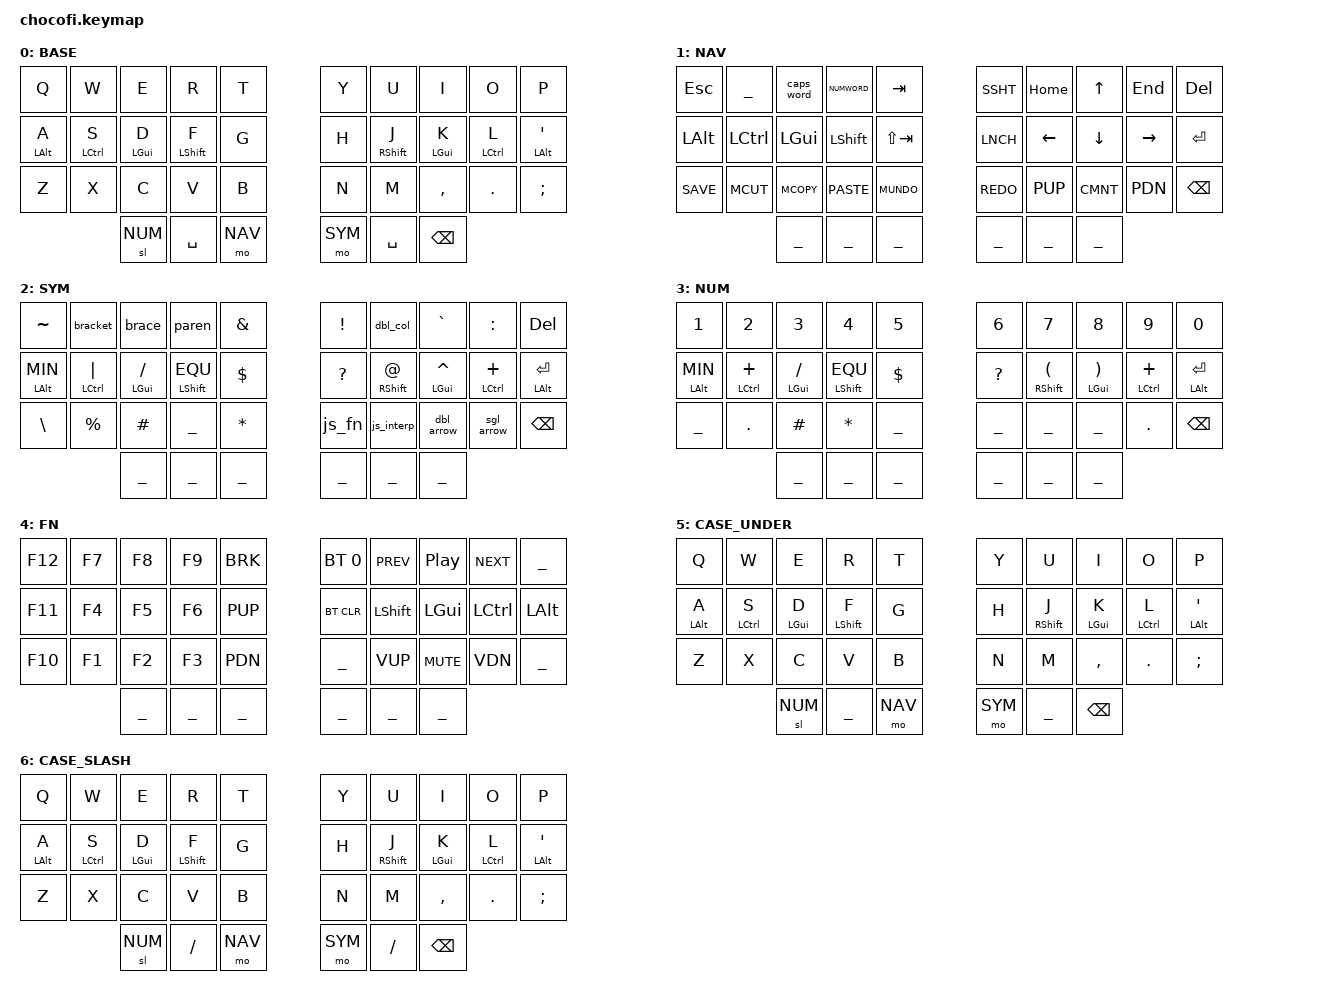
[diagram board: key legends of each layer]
/*
 * Copyright (c) 2020 The ZMK Contributors
 *
 * SPDX-License-Identifier: MIT
 */

#include <behaviors.dtsi>
#include <dt-bindings/zmk/keys.h>
#include <dt-bindings/zmk/bt.h>
#include <behaviors/num_word.dtsi>
#include "zmk-helpers/helper.h"
#include "zmk-helpers/key-labels/36.h"

#define BASE        0
#define NAV         1
#define SYM         2
#define NUM         3
#define FN          4
#define CASE_UNDER  5
#define CASE_SLASH  6

#define QUICK_TAP_MS 75

#include "keycodes.dtsi"
#include "autolayer.dtsi"
#include "layers.dtsi"
#include "combos.dtsi"

/ {
        keymap {
                compatible = "zmk,keymap";

                BASE {
// ------------------------------------------------------------------
// |  Q  |  W  |  E  |  R  |  T  |   |  Y  |  U  |  I   |  O  |  P  |
// |  A  |  S  |  D  |  F  |  G  |   |  H  |  J  |  K   |  L  |  '  |
// |  Z  |  X  |  C  |  V  |  B  |   |  N  |  M  |  ,   |  .  |  ;  |
//             | NUM | SPC | NAV |   | SYM | SPC | BSPC |
                        bindings = <
   &kp Q       &kp W        &kp E       &kp R        &kp T     &kp Y &kp U        &kp I       &kp O        &kp P   
   &hml LALT A &hml LCTRL S &hml LGUI D &hml LSHFT F &kp G     &kp H &hmr RSHFT J &hmr LGUI K &hmr LCTRL L &hmr LALT SQT
   &kp Z       &kp X        &kp C       &kp V        &kp B     &kp N &kp M        &kp COMMA   &kp DOT      &kp SEMI
                                  &sl NUM &kp SPACE &mo NAV    &mo SYM &kp SPACE &kp BSPC
                        >;
                };
                    
                NAV {
// --------------------------------------------------------------------------------------------------
// | ESC  | CASE_PATH  |  CASE_CAPS  | numword |  Tab   |   | ssht   | home |  up   |  end  |  del  |
// | LA   | LC         | LG          | LS      | LS(Tb) |   | launch | left |  down | right | enter |
// | save | cut        | copy        | paste   | undo   |   | redo   | pgup |  cmnt | pgdn  |  bspc |
//                                 | NUM | SPC | NAV    |   | SYM | SPC | BSPC |
                        bindings = <
   &kp ESC   ___       &caps_word NUMWORD   &kp TAB        SSHT &kp HOME &kp UP   &kp END   &kp DEL 
   &kp LALT  &kp LCTRL &kp LGUI  &kp LSHFT &kp LS(TAB)    LNCH &kp LEFT &kp DOWN &kp RIGHT &kp RET
   SAVE      MCUT      MCOPY     PASTE     MUNDO          REDO &kp PUP  CMNT     &kp PDN   &kp BSPC
                          	           ___ ___ ___   ___ ___ ___
                        >;
                };

                SYM {
// -----------------------------------------------------------------
// |  ~  | [] | {} | () |  &  |   |  !  |  ::   |  `  |  :  | del  |
// |  -  |  | |  / |  = |  $  |   |  ?  |  @    |  ^  |  +  | ret  |
// |  \  |  % |  # |  _ |  *  |   |  fn | `${}` |  => |  -> | back |
//             | NUM | SPC | NAV |   | SYM | SPC | BSPC |
                        bindings = <
   &kp TILDE     &bracket        &brace         &paren         &kp AMPS     &kp EXCL  &dbl_col      &kp GRAVE       &kp COLON       &kp DEL
   &hml LALT MIN &hml LCTRL PIPE &hml LGUI FSLH &hml LSHFT EQU &kp DLLR     &kp QMARK &hmr RSHFT AT &hmr LGUI CARET &hmr LCTRL PLUS &hmr LALT RET
   &kp BSLH      &kp PRCNT       &kp HASH       &kp UNDER      &kp ASTRK    &js_fn    &js_interp    &dbl_arrow      &sgl_arrow      &kp BSPC
                    	                                     ___ ___ ___   ___ ___ ___
                        >;
                };

                NUM {
// -----------------------------------------------------------------------------------------
// | 1 | 2 | 3 | 4 | 5 |   | 6 | 7 | 8 | 9 | 0   |
// | - | + | / | = | $ |   | ? | ( | ) | + | ret |
// |   | . | # | * |   |   |   |   |   |   | bspc |
//             | NUM | SPC | NAV |   | SYM | SPC | BSPC |
                        bindings = <
   &kp N1        &kp N2          &kp N3         &kp N4         &kp N5       &kp N6    &kp N7          &kp N8         &kp N9          &kp N0
   &hml LALT MIN &hml LCTRL PLUS &hml LGUI FSLH &hml LSHFT EQU &kp DLLR     &kp QMARK &hmr RSHFT LPAR &hmr LGUI RPAR &hmr LCTRL PLUS &hmr LALT RET
   ___           &kp DOT         &kp HASH       &kp ASTRK      ___          ___       ___             ___            &kp DOT         &kp BSPC
                          	                             ___ ___ ___   ___ ___ ___
                        >;
                };

                FN {
// -----------------------------------------------------------------------------------------
// | f12 | f7 | f8 | f9 | BRK |   | BT0   | PREV | PLAY | NEXT |    |
// | f11 | f4 | f5 | f6 | PUP |   | BTCLR | LS   | LG   | LC   | LA |
// | f10 | f1 | f2 | f3 | PDN |   |       | VUP  | MUTE | VDN  |    |
//          | NUM | SPC | NAV |   | SYM | SPC | BSPC |
                        bindings = <
   &kp F12 &kp F7 &kp F8 &kp F9 &kp BRK    &bt BT_SEL 0 &kp C_PREV &kp C_PP   &kp C_NEXT ___
   &kp F11 &kp F4 &kp F5 &kp F6 &kp PUP    &bt BT_CLR   &kp LSHFT  &kp LGUI   &kp LCTRL  &kp LALT
   &kp F10 &kp F1 &kp F2 &kp F3 &kp PDN    ___          &kp VUP    &kp C_MUTE &kp VDN    ___
                             ___ ___ ___   ___ ___ ___
                        >;
                };

                CASE_UNDER {
// ------------------------------------------------------------------
// |  Q  |  W  |  E  |  R  |  T  |   |  Y  |  U  |  I   |  O  |  P  |
// |  A  |  S  |  D  |  F  |  G  |   |  H  |  J  |  K   |  L  |  '  |
// |  Z  |  X  |  C  |  V  |  B  |   |  N  |  M  |  ,   |  .  |  ;  |
//             | NUM | _ | NAV |   | SYM | _ | BSPC |
                        bindings = <
   &kp Q       &kp W        &kp E       &kp R        &kp T     &kp Y &kp U        &kp I       &kp O        &kp P   
   &hml LALT A &hml LCTRL S &hml LGUI D &hml LSHFT F &kp G     &kp H &hmr RSHFT J &hmr LGUI K &hmr LCTRL L &hmr LALT SQT
   &kp Z       &kp X        &kp C       &kp V        &kp B     &kp N &kp M        &kp COMMA   &kp DOT      &kp SEMI
                                  &sl NUM &kp UNDER &mo NAV    &mo SYM &kp UNDER &kp BSPC
                        >;
                };

                CASE_SLASH {
// ------------------------------------------------------------------
// |  Q  |  W  |  E  |  R  |  T  |   |  Y  |  U  |  I   |  O  |  P  |
// |  A  |  S  |  D  |  F  |  G  |   |  H  |  J  |  K   |  L  |  '  |
// |  Z  |  X  |  C  |  V  |  B  |   |  N  |  M  |  ,   |  .  |  ;  |
//             | NUM | / | NAV |   | SYM | / | BSPC |
                        bindings = <
   &kp Q       &kp W        &kp E       &kp R        &kp T     &kp Y &kp U        &kp I       &kp O        &kp P   
   &hml LALT A &hml LCTRL S &hml LGUI D &hml LSHFT F &kp G     &kp H &hmr RSHFT J &hmr LGUI K &hmr LCTRL L &hmr LALT SQT
   &kp Z       &kp X        &kp C       &kp V        &kp B     &kp N &kp M        &kp COMMA   &kp DOT      &kp SEMI
                                  &sl NUM &kp SLASH &mo NAV    &mo SYM &kp SLASH &kp BSPC
                        >;
                };
        };
};
